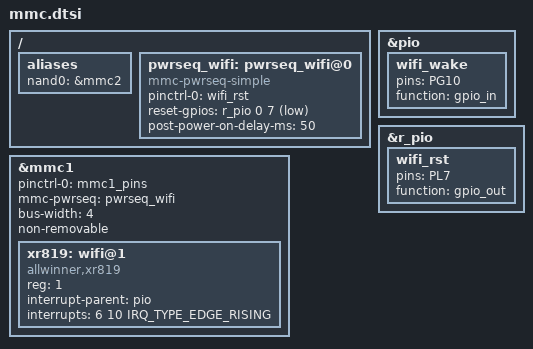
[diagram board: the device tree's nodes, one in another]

/*
	
	[    1.316766] sunxi-mmc 1c10000.mmc: initialized, max. request size: 16384 KB, uses new timings mode
	[    3.283704] sunxi-mmc 1c0f000.mmc: Got CD GPIO
	[    3.307189] sunxi-mmc 1c11000.mmc: initialized, max. request size: 2048 KB
	[    3.307552] sunxi-mmc 1c0f000.mmc: initialized, max. request size: 16384 KB, uses new timings mode

	uboot:
	mmc@1c0f000: 0 (SD)
	mmc@1c11000: 1 (eMMC)

*/

/ {
	aliases {
		nand0 = &mmc2;
	};
	
	/*
		***r_pio(0x9d) 11 7 0x01 0xffffffff 0xffffffff 0x00 
		***r_pio(0x9d) 0x0b 0 0x01 0xffffffff 0xffffffff 0x00 
		***pio(0x3a) 0x06 10 0x00 0xffffffff 0xffffffff 0x00 
		***pio(0x3a) 0x06 12 0x01 0xffffffff 0xffffffff 0x00 
		***pio(0x3a) 0x00 12 0x01 0xffffffff 0xffffffff 0x01 

		aosp: wlan {
			compatible = "allwinner,sunxi-wlan";
			clocks = <0x9c>;
			wlan_power = "vcc-wifi";
			wlan_io_regulator = "vcc-wifi-io";
			wlan_busnum = <0x01>;
			status = "okay";
			device_type = "wlan";
			wlan_usbnum = <0x03>;
			wlan_en = <0x9d 0x0b 7 0x01 0xffffffff 0xffffffff 0x00>;
			wlan_regon = <0x9d 0x0b 0 0x01 0xffffffff 0xffffffff 0x00>;
			wlan_hostwake = <0x3a 0x06 10 0x00 0xffffffff 0xffffffff 0x00>;
		};
		aosp: bt {
			compatible = "allwinner,sunxi-bt";
			clocks = <0x9c>;
			bt_power = "vcc-wifi";
			bt_io_regulator = "vcc-wifi-io";
			status = "okay";
			device_type = "bt";
			bt_rst_n = <0x3a 0x06 12 0x01 0xffffffff 0xffffffff 0x00>;
		};
	*/

	/*vdd_wifi: vdd_wifi {
		compatible = "regulator-fixed";
		regulator-name = "wifi";
		regulator-min-microvolt = <1800000>;
		regulator-max-microvolt = <1800000>;
		gpio = <&pio 0 12 GPIO_ACTIVE_HIGH>;
		startup-delay-us = <70000>;
		enable-active-high;
	};*/

	pwrseq_wifi: pwrseq_wifi@0 {
		compatible = "mmc-pwrseq-simple";
		pinctrl-names = "default";
		pinctrl-0 = <&wifi_rst>;

		/* real good,  gpio-359 (wlan_en_1           ) out hi				[pin 359 (PL7): (MUX UNCLAIMED) 1f02c00.pinctrl:359] WIFI 1.8V (LEFT 0Om) */
		/* unk. i.e. equal to pinctrl? */
		reset-gpios = <&r_pio 0 7 GPIO_ACTIVE_LOW>;
		post-power-on-delay-ms = <50>;
	};
};

&pio {
	wifi_wake: wifi_wake {
		/* unk, pin 202 (PG10): 1c22400.daudio (GPIO UNCLAIMED) function pcm1 group PG10*/
		pins = "PG10";
		function = "gpio_in";
    };
};

&r_pio {
	wifi_rst: wifi_rst {
		/* real good,  gpio-359 (wlan_en_1           ) out hi				[pin 359 (PL7): (MUX UNCLAIMED) 1f02c00.pinctrl:359] WIFI 1.8V (LEFT 0Om) */
		pins = "PL7";
		function = "gpio_out";
    };
};

// MMC1

/*
	aosp: sdmmc@1C10000 {
		compatible = "allwinner,sunxi-mmc-v4p1x";
		device_type = "sdc1";
		reg = <0x00 0x1c10000 0x00 0x1000>;
		interrupts = <0x00 0x3d 0x104>;
		clocks = <0x06 0x53 0x5e 0x5f 0x60>;
		clock-names = "osc24m\0pll_periph\0mmc\0ahb\0rst";
		pinctrl-names = "default\0sleep";
		pinctrl-1 = <0x62>;
		max-frequency = <0x8f0d180>;
		bus-width = <0x04>;
		sunxi-dly-52M-ddr4 = <0x01 0x00 0x00 0x00 0x02>;
		sunxi-dly-104M = <0x01 0x00 0x00 0x00 0x01>;
		sunxi-dly-208M = <0x01 0x00 0x00 0x00 0x01>;
		status = "okay";
		pinctrl-0 = <0xc6>;
		sd-uhs-sdr50;
		sd-uhs-ddr50;
		sd-uhs-sdr104;
		cap-sdio-irq;
		keep-power-in-suspend;
		ignore-pm-notify;
	};
*/

&mmc1 {
	#address-cells = <1>;
	#size-cells = <0>;

	pinctrl-names = "default";
	pinctrl-0 = <&mmc1_pins>;
	/*vmmc-supply = <&vdd_wifi>;*/
	mmc-pwrseq = <&pwrseq_wifi>;
	bus-width = <4>;
	non-removable;
	status = "okay"; 

	xr819: wifi@1 {
		reg = <1>;
		compatible = "allwinner,xr819";
		interrupt-parent = <&pio>;
		interrupts = <6 10 IRQ_TYPE_EDGE_RISING>;
	};
};




